# jbr_MDR1901VC1T register map
Registers are 32-bit, access not given, no defined reset value unless marked. A register's access mark holds for its fields unless they carry their own. Addresses are absolute; registers are grouped by the start of their names; [hi:lo] are bit positions; {n}, {i} and the like mark numbered series.

## BKP
{0x400D8000+4i} BKP_REG_{i:02} (i=0..9)
  [31:0] BKP_REG
0x400D8028 BKP_REG_0A
  [31:0] BKP_REG
0x400D802C BKP_REG_0B
  [31:0] BKP_REG
0x400D8030 BKP_REG_0C
  [31:0] BKP_REG
0x400D8034 BKP_REG_0D
  [31:0] BKP_REG
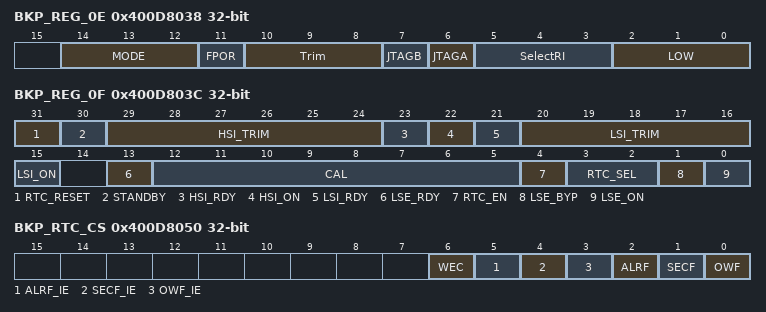
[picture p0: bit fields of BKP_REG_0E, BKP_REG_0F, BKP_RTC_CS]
0x400D8038 BKP_REG_0E
  [14:12] MODE, [11] FPOR, [10:8] Trim, [7] JTAGB, [6] JTAGA, [5:3] SelectRI, [2:0] LOW
0x400D803C BKP_REG_0F
  [31] RTC_RESET, [30] STANDBY, [29:24] HSI_TRIM, [23] HSI_RDY, [22] HSI_ON, [21] LSI_RDY, [20:16] LSI_TRIM, [15] LSI_ON, [13] LSE_RDY, [12:5] CAL, [4] RTC_EN, [3:2] RTC_SEL, [1] LSE_BYP, [0] LSE_ON
0x400D8040 BKP_RTC_CNT
  [31:0] RTC_CNT
0x400D8044 BKP_RTC_DIV
  [19:0] RTC_DIV
0x400D8048 BKP_RTC_PRL
  [19:0] RTC_PRL
0x400D804C BKP_RTC_ALRM
  [31:0] RTC_ALRM
0x400D8050 BKP_RTC_CS
  [6] WEC, [5] ALRF_IE, [4] SECF_IE, [3] OWF_IE, [2] ALRF, [1] SECF, [0] OWF

## EBC
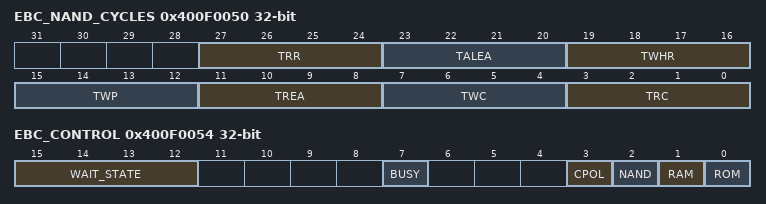
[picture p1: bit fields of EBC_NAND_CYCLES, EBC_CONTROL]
0x400F0050 EBC_NAND_CYCLES
  [27:24] TRR, [23:20] TALEA, [19:16] TWHR, [15:12] TWP, [11:8] TREA, [7:4] TWC, [3:0] TRC
0x400F0054 EBC_CONTROL
  [15:12] WAIT_STATE, [7] BUSY, [3] CPOL, [2] NAND, [1] RAM, [0] ROM

## DSP
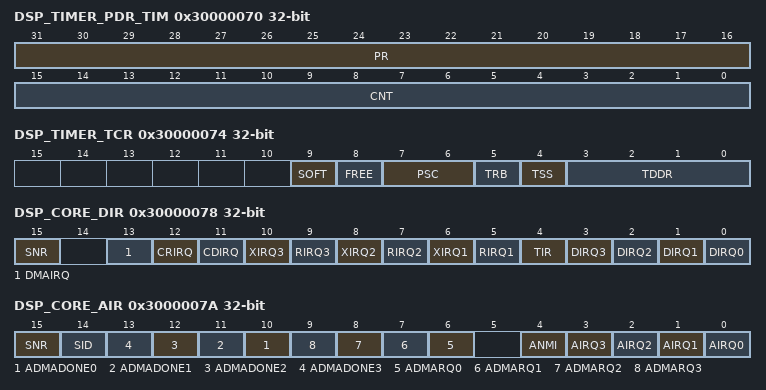
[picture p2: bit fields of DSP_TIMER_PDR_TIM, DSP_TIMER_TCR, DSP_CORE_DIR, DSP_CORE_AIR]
0x30000070 DSP_TIMER_PDR_TIM
  [31:16] PR, [15:0] CNT
0x30000074 DSP_TIMER_TCR
  [9] SOFT, [8] FREE, [7:6] PSC, [5] TRB, [4] TSS, [3:0] TDDR
0x30000078 DSP_CORE_DIR
  [15] SNR, [13] DMAIRQ, [12] CRIRQ, [11] CDIRQ, [10] XIRQ3, [9] RIRQ3, [8] XIRQ2, [7] RIRQ2, [6] XIRQ1, [5] RIRQ1, [4] TIR, [n] DIRQ{n} (n=0..3)
0x3000007A DSP_CORE_AIR
  [15] SNR, [14] SID, [n+10] ADMADONE{n} (n=0..3), [n+6] ADMARQ{n} (n=0..3), [4] ANMI, [n] AIRQ{n} (n=0..3)
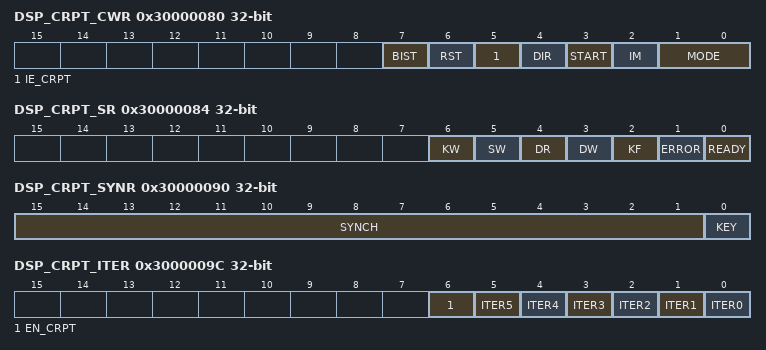
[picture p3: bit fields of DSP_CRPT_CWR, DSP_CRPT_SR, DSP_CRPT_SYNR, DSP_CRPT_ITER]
0x30000080 DSP_CRPT_CWR
  [7] BIST, [6] RST, [5] IE_CRPT, [4] DIR, [3] START, [2] IM, [1:0] MODE
0x30000084 DSP_CRPT_SR
  [6] KW, [5] SW, [4] DR, [3] DW, [2] KF, [1] ERROR, [0] READY
0x30000088 DSP_CRPT_DATA
  [15:0] DATA
0x3000008C DSP_CRPT_KR
  [15:0] KEY
0x30000090 DSP_CRPT_SYNR
  [15:1] SYNCH, [0] KEY
0x30000094 DSP_CRPT_CR
  [15:0] CONST
0x30000098 DSP_CRPT_IMIT
  [15:0] IMIT
0x3000009C DSP_CRPT_ITER
  [6] EN_CRPT, [n] ITER{n} (n=0..5)
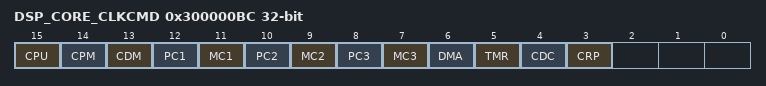
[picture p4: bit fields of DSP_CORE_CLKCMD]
0x300000BC DSP_CORE_CLKCMD
  [15] CPU, [14] CPM, [13] CDM, [12] PC1, [11] MC1, [10] PC2, [9] MC2, [8] PC3, [7] MC3, [6] DMA, [5] TMR, [4] CDC, [3] CRP
0x300000C0 DSP_DMA_DMA_STATUS
0x300000C4 DSP_DMA_DMA_CONFIG
0x300000C8 DSP_DMA_CTRL_BASE_PTR
0x300000CC DSP_DMA_ALT_CTRL_BASE_PTR
0x300000D0 DSP_DMA_DMA_WAITONREG_STATUS
0x300000D4 DSP_DMA_CHNL_SW_REQUEST
0x300000D8 DSP_DMA_CHNL_USEBURST_SET
0x300000DC DSP_DMA_CHNL_USEBURST_CLR
0x300000E0 DSP_DMA_CHNL_REQ_MASK_SET
0x300000E4 DSP_DMA_CHNL_REQ_MASK_CLR
0x300000E8 DSP_DMA_CHNL_ENABLE_SET
0x300000EC DSP_DMA_CHNL_ENABLE_CLR
0x300000F0 DSP_DMA_CHNL_PRI_ALT_SET
0x300000F4 DSP_DMA_CHNL_PRI_ALT_CLR
0x300000F8 DSP_DMA_CHNL_PRIORITY_SET
0x300000FC DSP_DMA_CHNL_PRIORITY_CLR
0x30000100 DSP_DMA_ERR_CLR
  [0] chnl_priority_set

## AUDIO
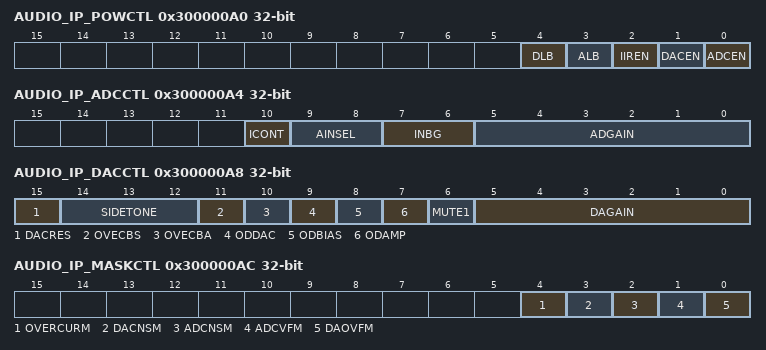
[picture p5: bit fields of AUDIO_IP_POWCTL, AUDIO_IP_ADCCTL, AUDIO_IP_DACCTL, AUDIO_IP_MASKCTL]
0x300000A0 AUDIO_IP_POWCTL
  [4] DLB, [3] ALB, [2] IIREN, [1] DACEN, [0] ADCEN
0x300000A4 AUDIO_IP_ADCCTL
  [10] ICONT, [9:8] AINSEL, [7:6] INBG, [5:0] ADGAIN
0x300000A8 AUDIO_IP_DACCTL
  [15] DACRES, [14:12] SIDETONE, [11] OVECBS, [10] OVECBA, [9] ODDAC, [8] ODBIAS, [7] ODAMP, [6] MUTE1, [5:0] DAGAIN
0x300000AC AUDIO_IP_MASKCTL
  [4] OVERCURM, [3] DACNSM, [2] ADCNSM, [1] ADCVFM, [0] DAOVFM
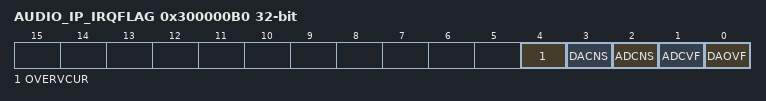
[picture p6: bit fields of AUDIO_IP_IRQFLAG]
0x300000B0 AUDIO_IP_IRQFLAG
  [4] OVERVCUR, [3] DACNS, [2] ADCNS, [1] ADCVF, [0] DAOVF
0x300000B4 AUDIO_IP_ADCREG
  [15:0] ADCSMP
0x300000B8 AUDIO_IP_DACREG
  [15:0] DACSMP

## SSP1
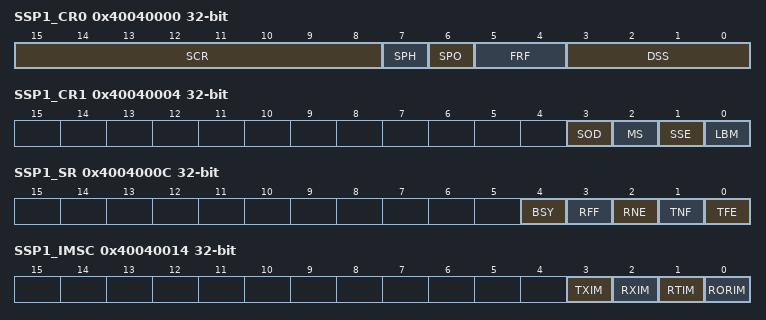
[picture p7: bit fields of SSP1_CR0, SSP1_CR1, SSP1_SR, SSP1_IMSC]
0x40040000 SSP1_CR0
  [15:8] SCR, [7] SPH, [6] SPO, [5:4] FRF, [3:0] DSS
0x40040004 SSP1_CR1
  [3] SOD, [2] MS, [1] SSE, [0] LBM
0x40040008 SSP1_DR
  [15:0] DATA
0x4004000C SSP1_SR
  [4] BSY, [3] RFF, [2] RNE, [1] TNF, [0] TFE
0x40040010 SSP1_CPSR
  [7:0] CPSDVSR
0x40040014 SSP1_IMSC
  [3] TXIM, [2] RXIM, [1] RTIM, [0] RORIM
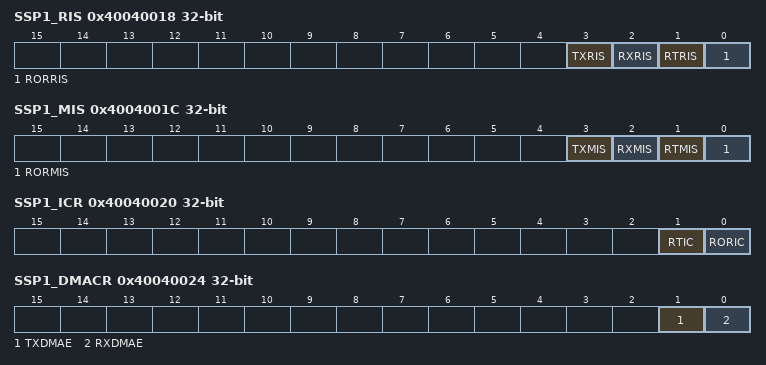
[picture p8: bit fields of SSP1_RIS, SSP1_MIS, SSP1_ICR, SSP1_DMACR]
0x40040018 SSP1_RIS
  [3] TXRIS, [2] RXRIS, [1] RTRIS, [0] RORRIS
0x4004001C SSP1_MIS
  [3] TXMIS, [2] RXMIS, [1] RTMIS, [0] RORMIS
0x40040020 SSP1_ICR
  [1] RTIC, [0] RORIC
0x40040024 SSP1_DMACR
  [1] TXDMAE, [0] RXDMAE
